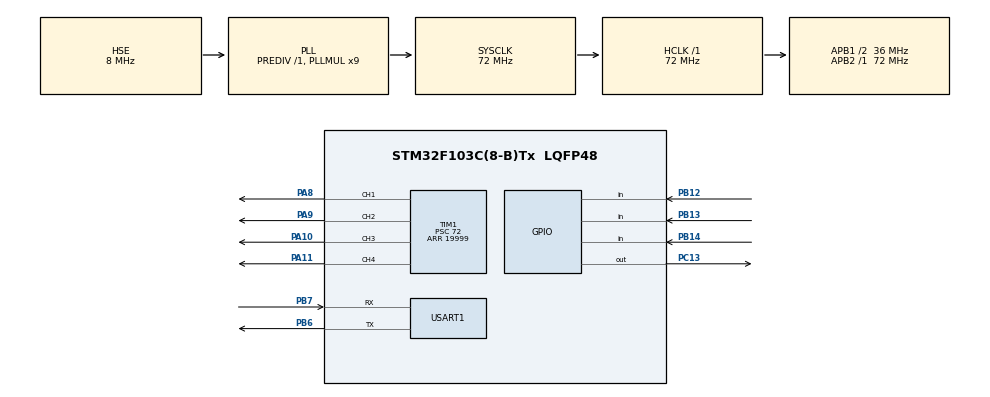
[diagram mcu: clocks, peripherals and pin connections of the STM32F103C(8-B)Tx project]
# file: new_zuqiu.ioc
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Dma.Request0=USART1_TX
Dma.USART1_TX.0.Direction=DMA_MEMORY_TO_PERIPH
Dma.USART1_TX.0.Instance=DMA1_Channel4
Dma.USART1_TX.0.MemDataAlignment=DMA_MDATAALIGN_BYTE
Dma.USART1_TX.0.MemInc=DMA_MINC_ENABLE
Dma.USART1_TX.0.Mode=DMA_NORMAL
Dma.USART1_TX.0.PeriphDataAlignment=DMA_PDATAALIGN_BYTE
Dma.USART1_TX.0.PeriphInc=DMA_PINC_DISABLE
Dma.USART1_TX.0.Priority=DMA_PRIORITY_LOW
Mcu.Family=STM32F1
Mcu.Name=STM32F103C(8-B)Tx
Mcu.Package=LQFP48
NVIC.DMA1_Channel4_IRQn=true\:0\:0\:false\:false\:true\:false\:true\:true
NVIC.PriorityGroup=NVIC_PRIORITYGROUP_4
NVIC.USART1_IRQn=true\:0\:0\:false\:false\:true\:false\:true\:true
PA10.Signal=S_TIM1_CH3
PA11.Signal=S_TIM1_CH4
PA13.Mode=Serial_Wire
PA13.Signal=SYS_JTMS-SWDIO
PA14.Mode=Serial_Wire
PA14.Signal=SYS_JTCK-SWCLK
PA8.Signal=S_TIM1_CH1
PA9.Signal=S_TIM1_CH2
PB12.GPIO_PuPd=GPIO_PULLUP
PB12.Signal=GPIO_Input
PB13.GPIO_PuPd=GPIO_PULLUP
PB13.Signal=GPIO_Input
PB14.GPIO_PuPd=GPIO_PULLUP
PB14.Signal=GPIO_Input
PB6.Mode=Asynchronous
PB6.Signal=USART1_TX
PB7.Mode=Asynchronous
PB7.Signal=USART1_RX
PC13-TAMPER-RTC.Signal=GPIO_Output
PD0-OSC_IN.Mode=HSE-External-Oscillator
PD0-OSC_IN.Signal=RCC_OSC_IN
PD1-OSC_OUT.Mode=HSE-External-Oscillator
PD1-OSC_OUT.Signal=RCC_OSC_OUT
ProjectManager.HeapSize=0x200
ProjectManager.StackSize=0x400
ProjectManager.TargetToolchain=MDK-ARM V5.32
RCC.AHBFreq_Value=72000000
RCC.APB1CLKDivider=RCC_HCLK_DIV2
RCC.APB1Freq_Value=36000000
RCC.APB1TimFreq_Value=72000000
RCC.APB2Freq_Value=72000000
RCC.APB2TimFreq_Value=72000000
RCC.HCLKFreq_Value=72000000
RCC.PLLMUL=RCC_PLL_MUL9
RCC.PLLSourceVirtual=RCC_PLLSOURCE_HSE
RCC.SYSCLKFreq_VALUE=72000000
RCC.SYSCLKSource=RCC_SYSCLKSOURCE_PLLCLK
RCC.USBFreq_Value=72000000
SH.S_TIM1_CH1.0=TIM1_CH1,PWM Generation1 CH1
SH.S_TIM1_CH2.0=TIM1_CH2,PWM Generation2 CH2
SH.S_TIM1_CH3.0=TIM1_CH3,PWM Generation3 CH3
SH.S_TIM1_CH4.0=TIM1_CH4,PWM Generation4 CH4
TIM1.Channel-PWM\ Generation1\ CH1=TIM_CHANNEL_1
TIM1.Channel-PWM\ Generation2\ CH2=TIM_CHANNEL_2
TIM1.Channel-PWM\ Generation3\ CH3=TIM_CHANNEL_3
TIM1.Channel-PWM\ Generation4\ CH4=TIM_CHANNEL_4
TIM1.OCIdleState_1=TIM_OCIDLESTATE_RESET
TIM1.OCPolarity_1=TIM_OCPOLARITY_LOW
TIM1.OCPolarity_2=TIM_OCPOLARITY_LOW
TIM1.OCPolarity_3=TIM_OCPOLARITY_LOW
TIM1.OCPolarity_4=TIM_OCPOLARITY_LOW
TIM1.Period=19999
TIM1.Prescaler=72
USART1.VirtualMode=VM_ASYNC
VP_TIM1_VS_ClockSourceINT.Mode=Internal
board=custom

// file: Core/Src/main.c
/* USER CODE BEGIN Header */
/**
  ******************************************************************************
  * @file           : main.c
  * @brief          : Main program body
  ******************************************************************************
  * @attention
  *
  * Copyright (c) 2026 STMicroelectronics.
  * All rights reserved.
  *
  * This software is licensed under terms that can be found in the LICENSE file
  * in the root directory of this software component.
  * If no LICENSE file comes with this software, it is provided AS-IS.
  *
  ******************************************************************************
  */
/* USER CODE END Header */
#include "main.h"
#include "dma.h"
#include "tim.h"
#include "usart.h"
#include "gpio.h"

/* USER CODE BEGIN Includes */
#include "BSP_SERVO.H"

/* USER CODE END Includes */

void SystemClock_Config(void);

/* USER CODE BEGIN 0 */
uint16_t tem_num=1500;
/* USER CODE END 0 */

int main(void)
{

  /* MCU Configuration--------------------------------------------------------*/

  /* Reset of all peripherals, Initializes the Flash interface and the Systick. */
  HAL_Init();

  /* Configure the system clock */
  SystemClock_Config();

  /* Initialize all configured peripherals */
  MX_GPIO_Init();
  MX_DMA_Init();
  MX_TIM1_Init();
  MX_USART1_UART_Init();
  /* USER CODE BEGIN 2 */
	Servo_Init();
  /* USER CODE END 2 */

  /* Infinite loop */
  /* USER CODE BEGIN WHILE */
  while (1)
  {
//				//???????
		HAL_GPIO_WritePin(GPIOC,GPIO_PIN_13,GPIO_PIN_SET);
		HAL_Delay(500);
		HAL_GPIO_WritePin(GPIOC,GPIO_PIN_13,GPIO_PIN_RESET);
		HAL_Delay(500);
//
////		qianjin();
//		tem_num+=100;
//		konzhi(tem_num);
//		if(tem_num>1800){
//			tem_num=1200;
//		}

//							/* ???????????? */
//			if (HAL_GPIO_ReadPin(GPIOB, GPIO_PIN_12) == GPIO_PIN_RESET)
//			{
//					/* ?? PB12 ??? */
//					HAL_GPIO_TogglePin(GPIOC, GPIO_PIN_13);
//					konzhi(1300);
//					/* ??????(?????),????????? */
//					HAL_Delay(20);
//					while (HAL_GPIO_ReadPin(GPIOB, GPIO_PIN_12) == GPIO_PIN_RESET)
//					{
//							// ?????????????
//					}
//			}
//
//
//			/* ???????????? */
//			if (HAL_GPIO_ReadPin(GPIOB, GPIO_PIN_14) == GPIO_PIN_RESET)
//			{
//					/* ?? PB12 ??? */
//					HAL_GPIO_TogglePin(GPIOC, GPIO_PIN_13);
//					konzhi(1500);
//					/* ??????(?????),????????? */
//					HAL_Delay(20);
//					while (HAL_GPIO_ReadPin(GPIOB, GPIO_PIN_14) == GPIO_PIN_RESET)
//					{
//							// ?????????????
//					}
//			}
//
//							/* ???????????? */
//			if (HAL_GPIO_ReadPin(GPIOB, GPIO_PIN_13) == GPIO_PIN_RESET)
//			{
//					/* ?? PB12 ??? */
//					HAL_GPIO_TogglePin(GPIOC, GPIO_PIN_13);
//					konzhi(1700);
//					/* ??????(?????),????????? */
//					HAL_Delay(20);
//					while (HAL_GPIO_ReadPin(GPIOB, GPIO_PIN_13) == GPIO_PIN_RESET)
//					{
//							// ?????????????
//					}
//			}

    /* USER CODE END WHILE */

  }
}

void SystemClock_Config(void)
{
  RCC_OscInitTypeDef RCC_OscInitStruct = {0};
  RCC_ClkInitTypeDef RCC_ClkInitStruct = {0};

  /** Initializes the RCC Oscillators according to the specified parameters
  * in the RCC_OscInitTypeDef structure.
  */
  RCC_OscInitStruct.OscillatorType = RCC_OSCILLATORTYPE_HSE;
  RCC_OscInitStruct.HSEState = RCC_HSE_ON;
  RCC_OscInitStruct.HSEPredivValue = RCC_HSE_PREDIV_DIV1;
  RCC_OscInitStruct.HSIState = RCC_HSI_ON;
  RCC_OscInitStruct.PLL.PLLState = RCC_PLL_ON;
  RCC_OscInitStruct.PLL.PLLSource = RCC_PLLSOURCE_HSE;
  RCC_OscInitStruct.PLL.PLLMUL = RCC_PLL_MUL9;
  if (HAL_RCC_OscConfig(&RCC_OscInitStruct) != HAL_OK)
  {
    Error_Handler();
  }

  /** Initializes the CPU, AHB and APB buses clocks
  */
  RCC_ClkInitStruct.ClockType = RCC_CLOCKTYPE_HCLK|RCC_CLOCKTYPE_SYSCLK
                              |RCC_CLOCKTYPE_PCLK1|RCC_CLOCKTYPE_PCLK2;
  RCC_ClkInitStruct.SYSCLKSource = RCC_SYSCLKSOURCE_PLLCLK;
  RCC_ClkInitStruct.AHBCLKDivider = RCC_SYSCLK_DIV1;
  RCC_ClkInitStruct.APB1CLKDivider = RCC_HCLK_DIV2;
  RCC_ClkInitStruct.APB2CLKDivider = RCC_HCLK_DIV1;

  if (HAL_RCC_ClockConfig(&RCC_ClkInitStruct, FLASH_LATENCY_2) != HAL_OK)
  {
    Error_Handler();
  }
}

void Error_Handler(void)
{
  __disable_irq();
  while (1)
  {
  }
}
